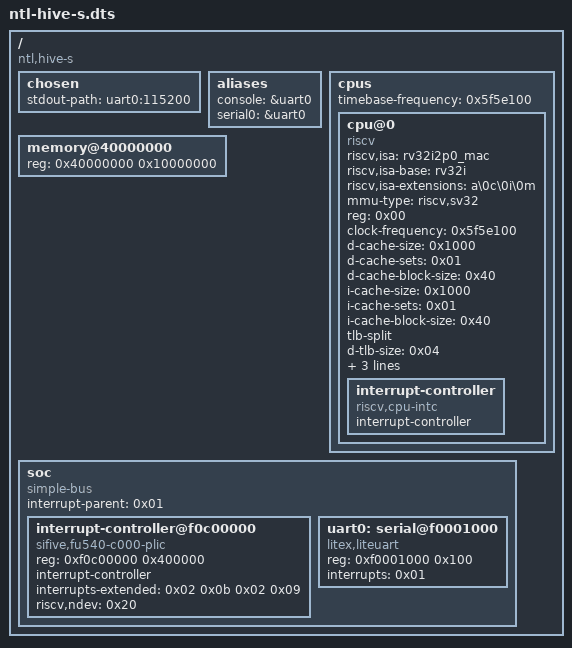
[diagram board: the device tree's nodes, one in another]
// SPDX-License-Identifier: (GPL-2.0 OR MIT)
/* Copyright (c) 2025 Kevin Schaerer <kevin.schaerer@nettimelogic.com> */

/dts-v1/;

/ {
	#address-cells = <0x01>;
	#size-cells = <0x01>;
	compatible = "ntl,hive-s";

	chosen {
		stdout-path = "uart0:115200";
	};

	aliases {
		console = &uart0;
		serial0 = &uart0;
	};

	cpus {
		#address-cells = <0x01>;
		#size-cells = <0x00>;
		timebase-frequency = <0x5f5e100>;

		cpu@0 {
			device_type = "cpu";
			compatible = "riscv";
			riscv,isa = "rv32i2p0_mac";
			riscv,isa-base = "rv32i";
			riscv,isa-extensions = "a\0c\0i\0m";
			mmu-type = "riscv,sv32";
			reg = <0x00>;
			clock-frequency = <0x5f5e100>;
			status = "okay";
			d-cache-size = <0x1000>;
			d-cache-sets = <0x01>;
			d-cache-block-size = <0x40>;
			i-cache-size = <0x1000>;
			i-cache-sets = <0x01>;
			i-cache-block-size = <0x40>;
			tlb-split;
			d-tlb-size = <0x04>;
			d-tlb-sets = <0x04>;
			i-tlb-size = <0x04>;
			i-tlb-sets = <0x04>;

			interrupt-controller {
				#address-cells = <0x00>;
				#interrupt-cells = <0x01>;
				interrupt-controller;
				compatible = "riscv,cpu-intc";
				phandle = <0x02>;
			};
		};
	};

	memory@40000000 {
		device_type = "memory";
		reg = <0x40000000 0x10000000>;
	};

	soc {
		#address-cells = <0x01>;
		#size-cells = <0x01>;
		compatible = "simple-bus";
		interrupt-parent = <0x01>;
		ranges;

		interrupt-controller@f0c00000 {
			compatible = "sifive,fu540-c000-plic\0sifive,plic-1.0.0";
			reg = <0xf0c00000 0x400000>;
			#address-cells = <0x00>;
			#interrupt-cells = <0x01>;
			interrupt-controller;
			interrupts-extended = <0x02 0x0b 0x02 0x09>;
			riscv,ndev = <0x20>;
			phandle = <0x01>;
		};

		uart0: serial@f0001000 {
			compatible = "litex,liteuart";
			reg = <0xf0001000 0x100>;
			interrupts = <0x01>;
			status = "okay";
		};
	};
};
